# LPC5411x register map
Vendor: nxp.com; File version: 1.2
CPU: CM4 r0p1, little endian, MPU, FPU, VTOR, vendor SysTick, 3 interrupt priority bits
Registers are 32-bit, read-write, reset 0x0 unless marked. A register's access mark holds for its fields unless they carry their own. Offsets are from the block's base; [hi:lo] are bit positions; {n}, {i} and the like mark numbered series.

## PINT — LPC5411x Pin interrupt and pattern match (PINT)
Base 0x40004000
0x00 ISEL — Pin Interrupt Mode register
  [7:0] PMODE — Selects the interrupt mode for each pin interrupt. Bit n configures the pin interrupt selected in PINTSELn. 0 = Edge sensitive 1 = Level sensitive
0x04 IENR — Pin interrupt level or rising edge interrupt enable register
  [7:0] ENRL — Enables the rising edge or level interrupt for each pin interrupt. Bit n configures the pin interrupt selected in PINTSELn. 0 = Disable rising edge or level interrupt. 1 = Enable rising edge or level interrupt.
0x08 SIENR reset not defined — Pin interrupt level or rising edge interrupt set register
  [7:0] SETENRL wo — Ones written to this address set bits in the IENR, thus enabling interrupts. Bit n sets bit n in the IENR register. 0 = No operation. 1 = Enable rising edge or level interrupt.
0x0C CIENR reset not defined — Pin interrupt level (rising edge interrupt) clear register
  [7:0] CENRL wo — Ones written to this address clear bits in the IENR, thus disabling the interrupts. Bit n clears bit n in the IENR register. 0 = No operation. 1 = Disable rising edge or level interrupt.
0x10 IENF — Pin interrupt active level or falling edge interrupt enable register
  [7:0] ENAF — Enables the falling edge or configures the active level interrupt for each pin interrupt. Bit n configures the pin interrupt selected in PINTSELn. 0 = Disable falling edge interrupt or set active interrupt level LOW. 1 = Enable falling edge interrupt enabled or set active interrupt level HIGH.
0x14 SIENF reset not defined — Pin interrupt active level or falling edge interrupt set register
  [7:0] SETENAF wo — Ones written to this address set bits in the IENF, thus enabling interrupts. Bit n sets bit n in the IENF register. 0 = No operation. 1 = Select HIGH-active interrupt or enable falling edge interrupt.
0x18 CIENF reset not defined — Pin interrupt active level or falling edge interrupt clear register
  [7:0] CENAF wo — Ones written to this address clears bits in the IENF, thus disabling interrupts. Bit n clears bit n in the IENF register. 0 = No operation. 1 = LOW-active interrupt selected or falling edge interrupt disabled.
0x1C RISE — Pin interrupt rising edge register
  [7:0] RDET — Rising edge detect. Bit n detects the rising edge of the pin selected in PINTSELn. Read 0: No rising edge has been detected on this pin since Reset or the last time a one was written to this bit. Write 0: no operation. Read 1: a rising edge has been detected since Reset or the last time a one was written to this bit. Write 1: clear rising edge detection for this pin.
0x20 FALL — Pin interrupt falling edge register
  [7:0] FDET — Falling edge detect. Bit n detects the falling edge of the pin selected in PINTSELn. Read 0: No falling edge has been detected on this pin since Reset or the last time a one was written to this bit. Write 0: no operation. Read 1: a falling edge has been detected since Reset or the last time a one was written to this bit. Write 1: clear falling edge detection for this pin.
0x24 IST — Pin interrupt status register
  [7:0] PSTAT — Pin interrupt status. Bit n returns the status, clears the edge interrupt, or inverts the active level of the pin selected in PINTSELn. Read 0: interrupt is not being requested for this interrupt pin. Write 0: no operation. Read 1: interrupt is being requested for this interrupt pin. Write 1 (edge-sensitive): clear rising- and falling-edge detection for this pin. Write 1 (level-sensitive): switch the active level for this pin (in the IENF register).
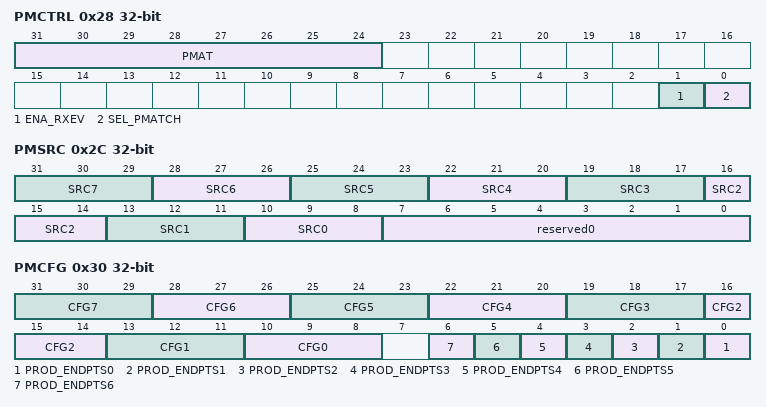
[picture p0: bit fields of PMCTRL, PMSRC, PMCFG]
0x28 PMCTRL — Pattern match interrupt control register
  [31:24] PMAT — This field displays the current state of pattern matches. A 1 in any bit of this field indicates that the corresponding product term is matched by the current state of the appropriate inputs.
  [1] ENA_RXEV — Enables the RXEV output to the CPU and/or to a GPIO output when the specified boolean expression evaluates to true.
    0=DISABLED (Disabled. RXEV output to the CPU is disabled.); 1=ENABLED (Enabled. RXEV output to the CPU is enabled.)
  [0] SEL_PMATCH — Specifies whether the 8 pin interrupts are controlled by the pin interrupt function or by the pattern match function.
    0=PIN_INTERRUPT (Pin interrupt. Interrupts are driven in response to the standard pin interrupt function.); 1=PATTERN_MATCH (Pattern match. Interrupts are driven in response to pattern matches.)
0x2C PMSRC (reset mask 0xFFFFFF00) — Pattern match interrupt bit-slice source register
  [3n+10:3n+8] SRC{n} (n=0..7) — Selects the input source for bit slice {n}
    {v}=INPUT{v} (Input {v}. Selects the pin selected in the PINTSEL{v} register as the source to bit slice {n}.) (v=0..7)
  [7:0] reserved0 wo — Software should not write 1s to unused bits.
0x30 PMCFG — Pattern match interrupt bit slice configuration register
  [3n+10:3n+8] CFG{n} (n=0..7) — Specifies the match contribution condition for bit slice {n}.
    0=CONSTANT_HIGH (Constant HIGH. This bit slice always contributes to a product term match.); 1=STICKY_RISING_EDGE (Sticky rising edge. Match occurs if a rising edge on the specified input has occurred since the last time the edge detection for this bit slice was cleared. This bit is only cleared when the PMCFG or the PMSRC registers are written to.); 2=STICKY_FALLING_EDGE (Sticky falling edge. Match occurs if a falling edge on the specified input has occurred since the last time the edge detection for this bit slice was cleared. This bit is only cleared when the PMCFG or the PMSRC registers are written to.); 3=STICKY_RISING_FALLING_EDGE (Sticky rising or falling edge. Match occurs if either a rising or falling edge on the specified input has occurred since the last time the edge detection for this bit slice was cleared. This bit is only cleared when the PMCFG or the PMSRC registers are written to.); 4=HIGH_LEVEL (High level. Match (for this bit slice) occurs when there is a high level on the input specified for this bit slice in the PMSRC register.); 5=LOW_LEVEL (Low level. Match occurs when there is a low level on the specified input.); 6=CONSTANT_ZERO (Constant 0. This bit slice never contributes to a match (should be used to disable any unused bit slices).); 7=EVENT (Event. Non-sticky rising or falling edge. Match occurs on an event - i.e. when either a rising or falling edge is first detected on the specified input (this is a non-sticky version of value 0x3) . This bit is cleared after one clock cycle.)
  [n] PROD_ENDPTS{n} (n=0..6) — Determines whether slice {n} is an endpoint.
    0=NO_EFFECT (No effect. Slice {n} is not an endpoint.); 1=ENDPOINT (endpoint. Slice {n} is the endpoint of a product term (minterm). Pin interrupt {n} in the NVIC is raised if the minterm evaluates as true.)
